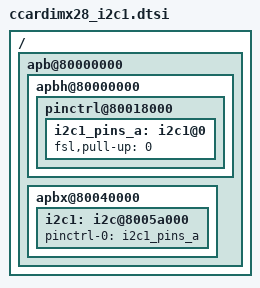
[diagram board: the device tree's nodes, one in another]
/*
 * Copyright 2013 Digi International, Inc.
 *
 * The code contained herein is licensed under the GNU General Public
 * License. You may obtain a copy of the GNU General Public License
 * Version 2 or later at the following locations:
 *
 * http://www.opensource.org/licenses/gpl-license.html
 * http://www.gnu.org/copyleft/gpl.html
 */

/ {
	apb@80000000 {
		apbh@80000000 {
			pinctrl@80018000 {
				pinctrl-names = "default";

				/* I2C1 has external pull-ups on module */
				i2c1_pins_a: i2c1@0 {
					fsl,pull-up = <0>;
				};
			};
		};

		apbx@80040000 {
			i2c1: i2c@8005a000 {
				pinctrl-names = "default";
				pinctrl-0 = <&i2c1_pins_a>;
				status = "okay";
			};
		};
	};
};
